AUTOSAR XML (schema 4-3-0)
standard types defined: uint8, uint8_DataConstr, boolean
package /ASP_DataTypes
  12 x impl type:
    brakeGain: category=VALUE, base-type=BaseTypes/uint8
    brakeGainEnabledRequest: category=VALUE, base-type=boolean, compu {0=Cx0_Off, 1=Cx1_On; unit Enum}
    brakeGainMaxDeceleration: category=VALUE, base-type=BaseTypes/uint8
    collisionThreatLevel: category=VALUE, base-type=BaseTypes/uint8, compu {0=Cx0_Ukwn, 1=Cx1_ThreatLo, 2=Cx2_ThreatMed, 3=Cx3_ThreatHi; unit Enum}
    decelerationRequested: category=VALUE, base-type=BaseTypes/uint8
    electricBeltRequest: category=VALUE, base-type=BaseTypes/uint8, compu {0=Cx0_NoActvn, 1=Cx1_ActvnFLo, 2=Cx2_ActvnFHi, 3=Cx3_NotInUse; unit Enum}
    enableDecelerationRequest: category=VALUE, base-type=boolean, compu {0=Cx0_Off, 1=Cx1_On; unit Enum}
    forwardCollisionWarningRequest: category=VALUE, base-type=boolean, compu {0=Cx0_Off, 1=Cx1_On; unit Enum}
    forwardCollWarningObjectType: category=VALUE, base-type=BaseTypes/uint8, compu {0=Cx0_UkwnClass, 1=Cx1_Car, 2=Cx2_Motorcycle, 3=Cx3_Truck, 4=Cx4_Ped, 5=Cx5_ObstclVert1, 6=Cx6_ObstclVert2, 7=Cx7_Anim, 8=Cx8_ObjGen, 9=Cx9_Bicycle, 10=CxA_VehOfUkwnClass; unit Enum}
    postEventMessageRequest: category=VALUE, base-type=BaseTypes/uint8, compu {0=Cx0_NoMsg, 1=Cx1_IntvLgt, 2=Cx2_IntvLat, 3=Cx3_IntvLgtAndIntvLat, 4=Cx4_BrkPls, 5=Cx5_CtaBrkMsg; unit Enum}
    SG_AEB_Output: category=STRUCTURE
      11 x element, all with category=TYPE_REFERENCE:
        collisionThreatLevel: range raw 0..3, implementation-data-type=collisionThreatLevel
        electricBeltRequest: range raw 0..3, implementation-data-type=electricBeltRequest
        forwardCollisionWarningRequest: implementation-data-type=forwardCollisionWarningRequest
        standStillRequest: implementation-data-type=standStillRequest
        brakeGain: range raw 0..31, implementation-data-type=brakeGain
        postEventMessageRequest: range raw 0..7, implementation-data-type=postEventMessageRequest
        brakeGainEnabledRequest: implementation-data-type=brakeGainEnabledRequest
        brakeGainMaxDeceleration: implementation-data-type=brakeGainMaxDeceleration
        enableDecelerationRequest: implementation-data-type=enableDecelerationRequest
        forwardCollWarningObjectType: range raw 0..15, implementation-data-type=forwardCollWarningObjectType
        decelerationRequested: implementation-data-type=decelerationRequested
    standStillRequest: category=VALUE, base-type=boolean, compu {0=Cx0_Off, 1=Cx1_On; unit Enum}
package /ASP_DataTypes/Units
  unit U_Enum: display-name=Enum, factor-si-to-unit=1, offset-si-to-unit=0
package /ASP_PortInterfaces
  sender receiver interface AEB_Output: invalidation-policy{data-element=AEB_Output, handle-invalid=DONT-INVALIDATE}
    data AEB_Output: type=SG_AEB_Output
package /ComponentTypes/FcaAdapSWC
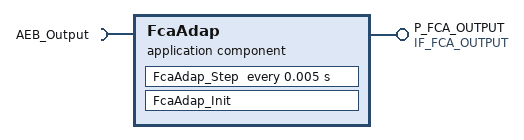
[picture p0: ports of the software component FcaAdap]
  application sw component type FcaAdap
    provide port P_FCA_OUTPUT: nonqueued-sender-com-spec{data-element=DE_FcaAdapOutput, init-value=constant-reference=CS_FCAAdap_FCA_Output}, provided-interface=IF_FCA_OUTPUT
    require port AEB_Output: nonqueued-receiver-com-spec{data-element=AEB_Output, filter=data-filter-type=ALWAYS, init-value=fields=[collisionThreatLevel:0, electricBeltRequest:0, forwardCollisionWarningRequest:0, standStillRequest:0, brakeGain:10, postEventMessageRequest:0, brakeGainEnabledRequest:0, brakeGainMaxDeceleration:0, enableDecelerationRequest:0, forwardCollWarningObjectType:0, decelerationRequested:0]}, required-interface=AEB_Output
    behavior FcaAdap_InternalBehavior
      init event FcaAdap_InitEvent: start-on-event=FcaAdap_Init
      timing event FcaAdap_Step_TE: start-on-event=FcaAdap_Step, period=0.005
      runnable FcaAdap_Init
        data-receive-point-by-arguments:
          access REC_AEB_Output_AEB_Output: accessed-variable=AEB_Output.AEB_Output
        data-send-points:
          access SEND_P_FCA_OUTPUT_DE_FcaAdapOutput: accessed-variable=P_FCA_OUTPUT.DE_FcaAdapOutput
      runnable FcaAdap_Step
        data-receive-point-by-arguments:
          access REC_AEB_Output_AEB_Output: accessed-variable=AEB_Output.AEB_Output
        data-send-points:
          access SEND_P_FCA_OUTPUT_DE_FcaAdapOutput: accessed-variable=P_FCA_OUTPUT.DE_FcaAdapOutput
  swc implementation FcaAdap_Implementation: behavior=FcaAdap_InternalBehavior
    code-descriptors:
      code Default: artifact-descriptors=autosar-engineering-object={short-label=Default, category=SWSRC}
package /ComponentTypes/FcaAdapSWC/Constants
  constant specification CS_FCAAdap_FCA_Output: value-spec=fields=[FCA_WrngLvlSta:0, FCA_VehStpReq:0, FCA_StbltActvReq:0, FCA_DclReqVal:0, FCA_PrefillActvReq:0, FCA_FullActvReq:0, FCA_TimetoCllsn:0, FCA_WrngTrgtDis:0, FCA_PartialActvReq:0]
package /ComponentTypes/FcaAdapSWC/DataTypes
  impl type FCA_OUTPUTS_T: category=STRUCTURE, type-emitter=RTE
    9 x element, all with category=TYPE_REFERENCE, implementation-data-type=uint8:
      FCA_WrngLvlSta
      FCA_VehStpReq
      FCA_StbltActvReq
      FCA_DclReqVal
      FCA_PrefillActvReq
      FCA_FullActvReq
      FCA_TimetoCllsn
      FCA_WrngTrgtDis
      FCA_PartialActvReq
package /ComponentTypes/FcaAdapSWC/PortInterfaces
  sender receiver interface IF_FCA_OUTPUT: invalidation-policy{data-element=DE_FcaAdapOutput, handle-invalid=DONT-INVALIDATE}
    data DE_FcaAdapOutput: type=FCA_OUTPUTS_T
